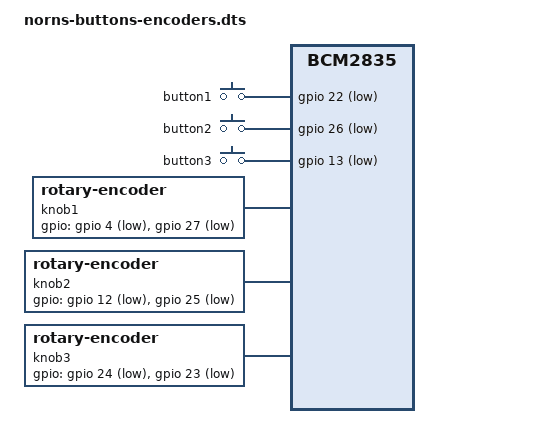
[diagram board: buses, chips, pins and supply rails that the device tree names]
/*
Device Tree overlay for the norns shield keys and encoders. From monome/linux
(5.10), for current Raspberry Pi kernels (6.x): the pin groups target &gpio
instead of the old "/soc/gpio" path (the node is gpio@7e200000 now).

The defaults are the shieldXL / norns shield 210330 pins (the old image set
them with dtparam in config.txt); the e*_pin_* / b*_pin parameters still work.

E1 = 4, 27    E2 = 12, 25    E3 = 24, 23
K1 = 22       K2 = 26        K3 = 13
*/

/dts-v1/;
/plugin/;

/ {
    compatible = "brcm,bcm2835";

    fragment@0 {
        target = <&gpio>;
        __overlay__ {
            knob_pins1: knob_pins1 {
                brcm,pins = <4 27>;
                brcm,function = <0>;
                brcm,pull = <2>;
            };
            knob_pins2: knob_pins2 {
                brcm,pins = <12 25>;
                brcm,function = <0>;
                brcm,pull = <2>;
            };
            knob_pins3: knob_pins3 {
                brcm,pins = <24 23>;
                brcm,function = <0>;
                brcm,pull = <2>;
            };
        };
    };

    fragment@1 {
        target-path = "/soc";
        __overlay__ {
            knob1: knob1 {
                compatible = "rotary-encoder";
                pinctrl-names = "default";
                pinctrl-0 = <&knob_pins1>;
                gpios = <&gpio 4 1>, <&gpio 27 1>;
                linux,axis = <0>; /* REL_X */
                rotary-encoder,relative-axis;
                rotary-encoder,half-period;
            };
            knob2: knob2 {
                compatible = "rotary-encoder";
                pinctrl-names = "default";
                pinctrl-0 = <&knob_pins2>;
                gpios = <&gpio 12 1>, <&gpio 25 1>;
                linux,axis = <0>;
                rotary-encoder,relative-axis;
                rotary-encoder,half-period;
            };
            knob3: knob3 {
                compatible = "rotary-encoder";
                pinctrl-names = "default";
                pinctrl-0 = <&knob_pins3>;
                gpios = <&gpio 24 1>, <&gpio 23 1>;
                linux,axis = <0>;
                rotary-encoder,relative-axis;
                rotary-encoder,half-period;
            };
        };
    };

    fragment@2 {
        target-path = "/";
        __overlay__ {
            keypad: keys {
                compatible = "gpio-keys";
                button1: button1 {
                    linux,code = <1>;
                    gpios = <&gpio 22 1>;
                };
                button2: button2 {
                    linux,code = <2>;
                    gpios = <&gpio 26 1>;
                };
                button3: button3 {
                    linux,code = <3>;
                    gpios = <&gpio 13 1>;
                };
            };
        };
    };

    __overrides__ {
        e1_pin_a = <&knob_pins1>,"brcm,pins:0",
                   <&knob1>,"gpios:4";
        e1_pin_b = <&knob_pins1>,"brcm,pins:4",
                   <&knob1>,"gpios:16";
        e2_pin_a = <&knob_pins2>,"brcm,pins:0",
                   <&knob2>,"gpios:4";
        e2_pin_b = <&knob_pins2>,"brcm,pins:4",
                   <&knob2>,"gpios:16";
        e3_pin_a = <&knob_pins3>,"brcm,pins:0",
                   <&knob3>,"gpios:4";
        e3_pin_b = <&knob_pins3>,"brcm,pins:4",
                   <&knob3>,"gpios:16";
        b1_pin = <&button1>,"gpios:4";
        b2_pin = <&button2>,"gpios:4";
        b3_pin = <&button3>,"gpios:4";
    };
};
